# CH592SFR register map
Vendor: WCH Ltd.; Series: CH59x; File version: 1.0
CPU: RISC-V r0p0, little endian, no MPU, no FPU, 2 interrupt priority bits
Registers are 8-bit, Read or Write, reset 0x0 unless marked. A register's access mark holds for its fields unless they carry their own. Offsets are from the block's base; [hi:lo] are bit positions.

## ADC — Analog to Digital Converter
Base 0x40001000
0x58 R8_ADC_CHANNEL reset 0xF — RW, ADC input channel selection
  [3:0] RB_ADC_CH_INX — RW, ADC input channel index
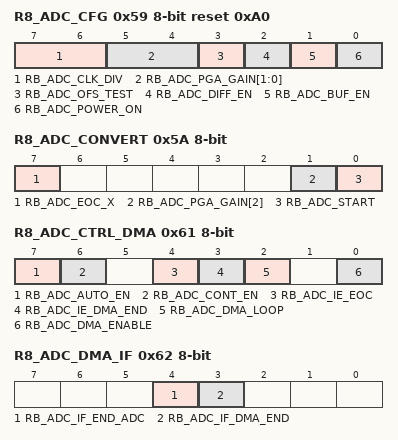
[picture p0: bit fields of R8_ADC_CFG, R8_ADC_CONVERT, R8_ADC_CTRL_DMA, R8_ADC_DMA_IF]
0x59 R8_ADC_CFG reset 0xA0 — RW, ADC configure
  [7:6] RB_ADC_CLK_DIV — RW, select ADC clock frequency: 00=3.2MHz, 01=2.67MHz, 10=5.33MHz, 11=4MHz
  [5:4] RB_ADC_PGA_GAIN[1:0] — RW, set ADC input PGA gain: 00=-12dB, 01=-6dB, 10=0dB, 11=6dB
  [3] RB_ADC_OFS_TEST — RW, enable ADC offset test mode: 0=normal mode, 1=short to test offset
  [2] RB_ADC_DIFF_EN — RW, ADC input channel mode: 0=single-end, 1=differnetial
  [1] RB_ADC_BUF_EN — RW, ADC input buffer enable
  [0] RB_ADC_POWER_ON — RW, ADC power control: 0=power down, 1=power on
0x5A R8_ADC_CONVERT — RW, ADC convert control
  [7] RB_ADC_EOC_X ro — RO, end of ADC conversion flag
  [1] RB_ADC_PGA_GAIN[2] — RW, ADC input PGA gain direction selection, combined with RB_ ADC_ PGA_ GAIN [1:0] usage
  [0] RB_ADC_START — RW, ADC convert start control: 0=stop ADC convert, 1=start an ADC convert, auto clear
0x5B R8_TEM_SENSOR — RW, temperature sensor control
  [7] RB_TEM_SEN_PWR_ON — RW, temperature sensor power control: 0=power down, 1=power on
0x5C R16_ADC_DATA 16-bit ro reset not defined — RO, ADC data
  [11:0] RB_ADC_DATA — RO, ADC conversion data
0x5E R8_ADC_INT_FLAG ro — RO, ADC interrupt flag register
  [7] RB_ADC_IF_EOC — RO, ADC conversion interrupt flag
0x61 R8_ADC_CTRL_DMA write-read — RW, ADC DMA control
  [7] RB_ADC_AUTO_EN — RW, enable auto continuing ADC for DMA
  [6] RB_ADC_CONT_EN — RW, enable contineous conversion ADC
  [4] RB_ADC_IE_EOC — RW, enable interrupt for end of ADC conversion
  [3] RB_ADC_IE_DMA_END — RW, enable interrupt for ADC DMA completion
  [2] RB_ADC_DMA_LOOP — RW, ADC DMA address loop enable
  [0] RB_ADC_DMA_ENABLE — RW, ADC DMA enable
0x62 R8_ADC_DMA_IF write-read — RW1, ADC and DMA interrupt flag registers
  [4] RB_ADC_IF_END_ADC — interrupt flag for end of ADC conversion
  [3] RB_ADC_IF_DMA_END — interrupt flag for ADC DMA completion
0x63 R8_ADC_AUTO_CYCLE write-read reset not defined — RO, ADC interrupt flag
  [7:0] R8_ADC_AUTO_CYCLE — auto ADC cycle value, unit is 16 Fsys
0x64 R16_ADC_DMA_NOW ro reset not defined — RO, ADC DMA current address
  [14:1] R16_ADC_DMA_NOW — ADC DMA current address
0x68 R16_ADC_DMA_BEG write-read reset not defined — RW, ADC DMA begin address
  [14:1] R16_ADC_DMA_BEG — ADC DMA begin address
0x6C R16_ADC_DMA_END write-read reset not defined — RW, ADC DMA end address
  [14:1] R16_ADC_DMA_END — ADC DMA end address

## GPIO — General porpose intput output
Base 0x40001000
0x90 R16_PA_INT_EN 16-bit — RW, GPIO PA interrupt enable
  [15:0] R16_PA_INT_EN — GPIO PA interrupt enable
0x92 R16_PB_INT_EN 16-bit — RW, GPIO PB interrupt enable
  [15:0] R16_PB_INT_EN — GPIO PB interrupt enable
0x94 R16_PA_INT_MODE 16-bit — RW, GPIO PA interrupt mode: 0=level action, 1=edge action
  [15:0] R16_PA_INT_MODE — GPIO PA interrupt mode
0x96 R16_PB_INT_MODE 16-bit — RW, GPIO PB interrupt mode: 0=level action, 1=edge action;RW, status for parallel slave read
  [15:0] R16_PB_INT_MODE — GPIO PB interrupt mode
0x9C R16_PA_INT_IF 16-bit — RW1, GPIO PA interrupt flag
  [15:0] R16_PA_INT_IF — GPIO PA interrupt flag
0x9E R16_PB_INT_IF 16-bit — RW1, GPIO PB interrupt flag
  [15:0] R16_PB_INT_IF — GPIO PB interrupt flag
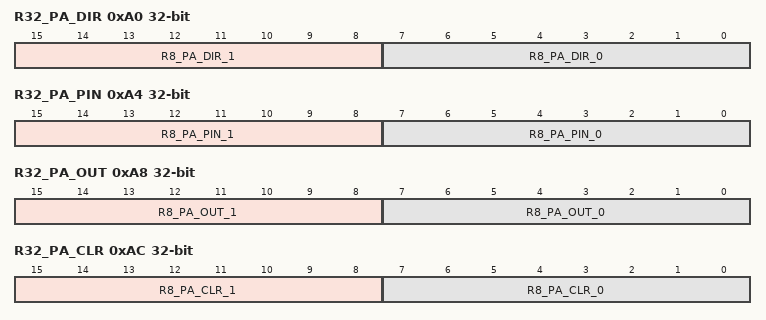
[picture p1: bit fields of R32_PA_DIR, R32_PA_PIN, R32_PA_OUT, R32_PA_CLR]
0xA0 R32_PA_DIR 32-bit — RW, GPIO PA I/O direction: 0=in, 1=out
  [15:8] R8_PA_DIR_1 — GPIO PA I/O direction byte 1
  [7:0] R8_PA_DIR_0 — GPIO PA I/O direction byte 0
0xA4 R32_PA_PIN 32-bit ro reset not defined — RO, GPIO PA input
  [15:8] R8_PA_PIN_1 — GPIO PA input byte 1
  [7:0] R8_PA_PIN_0 — GPIO PA input byte 0
0xA8 R32_PA_OUT 32-bit — RW, GPIO PA output
  [15:8] R8_PA_OUT_1 — GPIO PA output byte 1
  [7:0] R8_PA_OUT_0 — GPIO PA output byte 0
0xAC R32_PA_CLR 32-bit Write — WZ, GPIO PA clear output: 0=keep, 1=clear
  [15:8] R8_PA_CLR_1 — GPIO PA clear output byte 1
  [7:0] R8_PA_CLR_0 — GPIO PA clear output byte 0
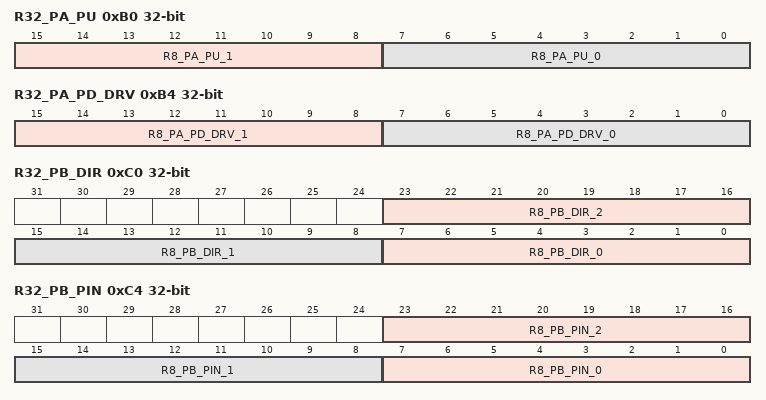
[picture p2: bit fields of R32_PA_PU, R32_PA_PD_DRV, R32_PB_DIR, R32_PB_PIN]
0xB0 R32_PA_PU 32-bit — RW, GPIO PA pullup resistance enable
  [15:8] R8_PA_PU_1 — GPIO PA pullup resistance enable byte 0
  [7:0] R8_PA_PU_0 — GPIO PA pullup resistance enable byte 0
0xB4 R32_PA_PD_DRV 32-bit — RW, PA pulldown for input or PA driving capability for output
  [15:8] R8_PA_PD_DRV_1 — PA pulldown for input or PA driving capability for output byte 1
  [7:0] R8_PA_PD_DRV_0 — PA pulldown for input or PA driving capability for output byte 0
0xC0 R32_PB_DIR 32-bit — RW, GPIO PB I/O direction: 0=in, 1=out
  [23:16] R8_PB_DIR_2 — GPIO PB I/O direction byte 2
  [15:8] R8_PB_DIR_1 — GPIO PB I/O direction byte 1
  [7:0] R8_PB_DIR_0 — GPIO PB I/O direction byte 0
0xC4 R32_PB_PIN 32-bit ro — RO, GPIO PB input
  [23:16] R8_PB_PIN_2 — GPIO PB input byte 2
  [15:8] R8_PB_PIN_1 — GPIO PB input byte 1
  [7:0] R8_PB_PIN_0 — GPIO PB input byte 0
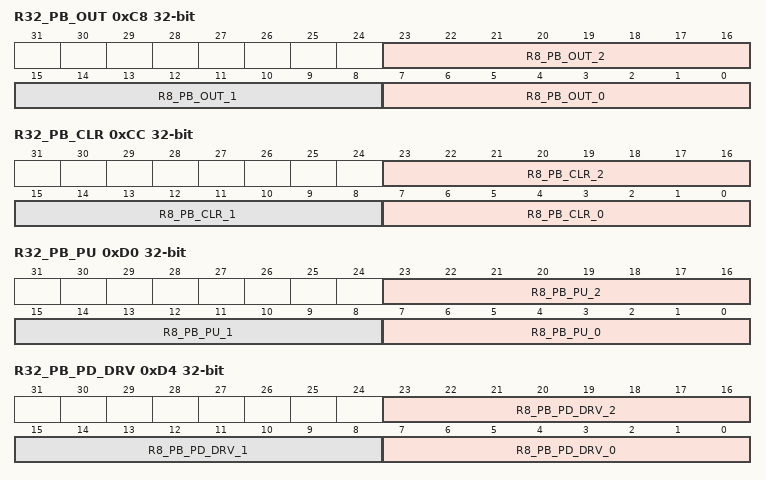
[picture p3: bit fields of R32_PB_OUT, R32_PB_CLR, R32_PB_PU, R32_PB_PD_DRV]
0xC8 R32_PB_OUT 32-bit — RW, GPIO PB output;RW, data for parallel slave read
  [23:16] R8_PB_OUT_2 — GPIO PB output byte 2
  [15:8] R8_PB_OUT_1 — GPIO PB output byte 1
  [7:0] R8_PB_OUT_0 — GPIO PB output byte 0
0xCC R32_PB_CLR 32-bit — WZ, GPIO PB clear output: 0=keep, 1=clear
  [23:16] R8_PB_CLR_2 — GPIO PB clear output byte 2
  [15:8] R8_PB_CLR_1 — GPIO PB clear output byte 1
  [7:0] R8_PB_CLR_0 — GPIO PB clear output byte 0
0xD0 R32_PB_PU 32-bit — RW, GPIO PB pullup resistance enable
  [23:16] R8_PB_PU_2 — GPIO PB pullup resistance enable byte 2
  [15:8] R8_PB_PU_1 — GPIO PB pullup resistance enable byte 1
  [7:0] R8_PB_PU_0 — GPIO PB pullup resistance enable byte 0
0xD4 R32_PB_PD_DRV 32-bit — RW, PB pulldown for input or PB driving capability for output
  [23:16] R8_PB_PD_DRV_2 — PB pulldown for input or PB driving capability for output byte 0
  [15:8] R8_PB_PD_DRV_1 — PB pulldown for input or PB driving capability for output byte 0
  [7:0] R8_PB_PD_DRV_0 — PB pulldown for input or PB driving capability for output byte 0
